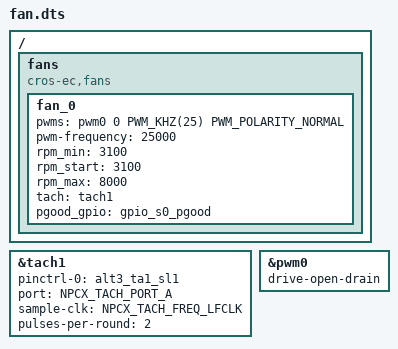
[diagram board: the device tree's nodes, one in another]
/* Copyright 2021 The Chromium OS Authors. All rights reserved.
 * Use of this source code is governed by a BSD-style license that can be
 * found in the LICENSE file.
 */

/ {
	fans {
		compatible = "cros-ec,fans";

		fan_0 {
			pwms = <&pwm0 0 PWM_KHZ(25) PWM_POLARITY_NORMAL>;
			pwm-frequency = <25000>;
			rpm_min = <3100>;
			rpm_start = <3100>;
			rpm_max = <8000>;
			tach = <&tach1>;
			pgood_gpio = <&gpio_s0_pgood>;
		};
	};
};

/* Tachemeter for fan speed measurement */
&tach1 {
	status = "okay";
	pinctrl-0 = <&alt3_ta1_sl1>; /* Use TA1 as input pin */
	port = <NPCX_TACH_PORT_A>; /* port-A is selected */
	sample-clk = <NPCX_TACH_FREQ_LFCLK>; /* Use LFCLK as sampling clock */
	pulses-per-round = <2>; /* number of pulses per round of encoder */
};

&pwm0 {
	status = "okay";
	drive-open-drain;
};
